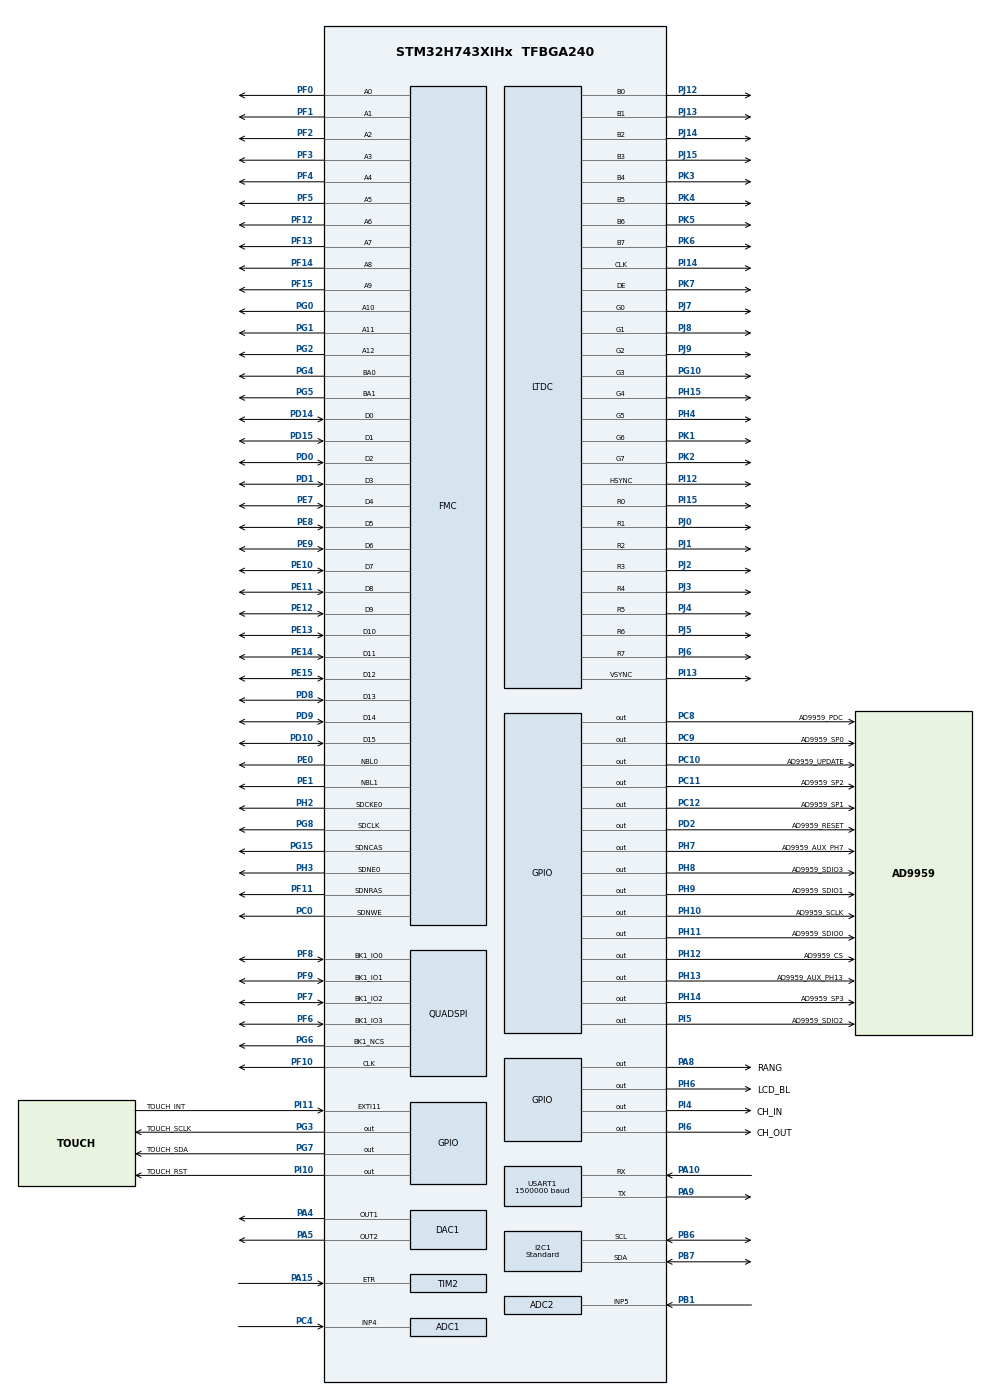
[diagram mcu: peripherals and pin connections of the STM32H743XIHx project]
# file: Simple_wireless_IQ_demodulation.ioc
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ADC1.Channel-0\#ChannelRegularConversion=ADC_CHANNEL_4
ADC1.ClockPrescaler=ADC_CLOCK_ASYNC_DIV2
ADC1.ConversionDataManagement=ADC_CONVERSIONDATA_DMA_CIRCULAR
ADC1.ExternalTrigConv=ADC_EXTERNALTRIG_T2_TRGO
ADC1.NbrOfConversionFlag=1
ADC1.OffsetNumber-0\#ChannelRegularConversion=ADC_OFFSET_NONE
ADC1.OffsetSignedSaturation-0\#ChannelRegularConversion=DISABLE
ADC1.Rank-0\#ChannelRegularConversion=1
ADC1.Resolution=ADC_RESOLUTION_14B
ADC1.SamplingTime-0\#ChannelRegularConversion=ADC_SAMPLETIME_1CYCLE_5
ADC1.master=1
ADC2.Channel-0\#ChannelRegularConversion=ADC_CHANNEL_5
ADC2.ClockPrescaler=ADC_CLOCK_ASYNC_DIV2
ADC2.ConversionDataManagement=ADC_CONVERSIONDATA_DMA_CIRCULAR
ADC2.ExternalTrigConv=ADC_EXTERNALTRIG_T2_TRGO
ADC2.NbrOfConversionFlag=1
ADC2.OffsetNumber-0\#ChannelRegularConversion=ADC_OFFSET_NONE
ADC2.OffsetSignedSaturation-0\#ChannelRegularConversion=DISABLE
ADC2.Rank-0\#ChannelRegularConversion=1
ADC2.Resolution=ADC_RESOLUTION_14B
ADC2.SamplingTime-0\#ChannelRegularConversion=ADC_SAMPLETIME_1CYCLE_5
CORTEX_M7.AccessPermission_Spec=MPU_REGION_FULL_ACCESS
CORTEX_M7.BaseAddress_Spec=0xC0000000
CORTEX_M7.CPU_DCache=Enabled
CORTEX_M7.CPU_ICache=Enabled
CORTEX_M7.DisableExec_Spec=MPU_INSTRUCTION_ACCESS_ENABLE
CORTEX_M7.IsCacheable_Spec=MPU_ACCESS_CACHEABLE
CORTEX_M7.IsShareable_Spec=MPU_ACCESS_NOT_SHAREABLE
CORTEX_M7.MPU_Control=MPU_HFNMI_PRIVDEF
CORTEX_M7.Size_Spec=MPU_REGION_SIZE_32MB
CORTEX_M7.SubRegionDisable_Spec=0x0
CORTEX_M7.default_mode_Activation=1
DAC1.DAC_Channel-DAC_OUT1=DAC_CHANNEL_1
DAC1.DAC_Channel-DAC_OUT2=DAC_CHANNEL_2
DAC1.DAC_Trigger-DAC_OUT1=DAC_TRIGGER_T2_TRGO
DAC1.DAC_Trigger-DAC_OUT2=DAC_TRIGGER_T2_TRGO
Dma.ADC1.0.Direction=DMA_PERIPH_TO_MEMORY
Dma.ADC1.0.EventEnable=DISABLE
Dma.ADC1.0.FIFOMode=DMA_FIFOMODE_DISABLE
Dma.ADC1.0.Instance=DMA1_Stream0
Dma.ADC1.0.MemDataAlignment=DMA_MDATAALIGN_HALFWORD
Dma.ADC1.0.MemInc=DMA_MINC_ENABLE
Dma.ADC1.0.Mode=DMA_CIRCULAR
Dma.ADC1.0.PeriphDataAlignment=DMA_PDATAALIGN_HALFWORD
Dma.ADC1.0.PeriphInc=DMA_PINC_DISABLE
Dma.ADC1.0.Polarity=HAL_DMAMUX_REQ_GEN_RISING
Dma.ADC1.0.Priority=DMA_PRIORITY_VERY_HIGH
Dma.ADC1.0.RequestNumber=1
Dma.ADC1.0.SignalID=NONE
Dma.ADC1.0.SyncEnable=DISABLE
Dma.ADC1.0.SyncPolarity=HAL_DMAMUX_SYNC_NO_EVENT
Dma.ADC1.0.SyncRequestNumber=1
Dma.ADC1.0.SyncSignalID=NONE
Dma.ADC2.1.Direction=DMA_PERIPH_TO_MEMORY
Dma.ADC2.1.EventEnable=DISABLE
Dma.ADC2.1.FIFOMode=DMA_FIFOMODE_DISABLE
Dma.ADC2.1.Instance=DMA2_Stream0
Dma.ADC2.1.MemDataAlignment=DMA_MDATAALIGN_HALFWORD
Dma.ADC2.1.MemInc=DMA_MINC_ENABLE
Dma.ADC2.1.Mode=DMA_CIRCULAR
Dma.ADC2.1.PeriphDataAlignment=DMA_PDATAALIGN_HALFWORD
Dma.ADC2.1.PeriphInc=DMA_PINC_DISABLE
Dma.ADC2.1.Polarity=HAL_DMAMUX_REQ_GEN_RISING
Dma.ADC2.1.Priority=DMA_PRIORITY_VERY_HIGH
Dma.ADC2.1.RequestNumber=1
Dma.ADC2.1.SignalID=NONE
Dma.ADC2.1.SyncEnable=DISABLE
Dma.ADC2.1.SyncPolarity=HAL_DMAMUX_SYNC_NO_EVENT
Dma.ADC2.1.SyncRequestNumber=1
Dma.ADC2.1.SyncSignalID=NONE
Dma.DAC1_CH2.2.Direction=DMA_MEMORY_TO_PERIPH
Dma.DAC1_CH2.2.EventEnable=DISABLE
Dma.DAC1_CH2.2.FIFOMode=DMA_FIFOMODE_DISABLE
Dma.DAC1_CH2.2.Instance=DMA1_Stream1
Dma.DAC1_CH2.2.MemDataAlignment=DMA_MDATAALIGN_HALFWORD
Dma.DAC1_CH2.2.MemInc=DMA_MINC_ENABLE
Dma.DAC1_CH2.2.Mode=DMA_CIRCULAR
Dma.DAC1_CH2.2.PeriphDataAlignment=DMA_PDATAALIGN_HALFWORD
Dma.DAC1_CH2.2.PeriphInc=DMA_PINC_DISABLE
Dma.DAC1_CH2.2.Polarity=HAL_DMAMUX_REQ_GEN_RISING
Dma.DAC1_CH2.2.Priority=DMA_PRIORITY_HIGH
Dma.DAC1_CH2.2.RequestNumber=1
Dma.DAC1_CH2.2.SignalID=NONE
Dma.DAC1_CH2.2.SyncEnable=DISABLE
Dma.DAC1_CH2.2.SyncPolarity=HAL_DMAMUX_SYNC_NO_EVENT
Dma.DAC1_CH2.2.SyncRequestNumber=1
Dma.DAC1_CH2.2.SyncSignalID=NONE
Dma.Request0=ADC1
Dma.Request1=ADC2
Dma.Request2=DAC1_CH2
FMC.CASLatency1=FMC_SDRAM_CAS_LATENCY_3
FMC.ColumnBitsNumber1=FMC_SDRAM_COLUMN_BITS_NUM_9
FMC.ExitSelfRefreshDelay1=7
FMC.LoadToActiveDelay1=2
FMC.RCDDelay1=2
FMC.RPDelay1=2
FMC.ReadBurst1=FMC_SDRAM_RBURST_ENABLE
FMC.ReadPipeDelay1=FMC_SDRAM_RPIPE_DELAY_1
FMC.RowCycleDelay1=7
FMC.SDClockPeriod1=FMC_SDRAM_CLOCK_PERIOD_2
FMC.SelfRefreshTime1=4
FMC.WriteRecoveryTime1=3
FREERTOS.BinarySemaphores01=AdcFrameReadySem,Dynamic,NULL,Depleted;SweepBlockReadySem,Dynamic,NULL,Available;DemodBlockReadySem,Dynamic,NULL,Available
FREERTOS.Queues01=DDSQueue,200,AppDdsCmd,0,Dynamic,NULL,NULL;PrintQueue,32,128,1,Dynamic,NULL,NULL;ModDetectQueue,8,uint32_t,0,Dynamic,NULL,NULL;DemodQueue,4,uint32_t,0,Dynamic,NULL,NULL
FREERTOS.Tasks01=DisplayTask,24,4096,StartDisplayTask,As weak,NULL,Dynamic,NULL,NULL;TouchTask,8,512,StartTouchTask,As weak,NULL,Dynamic,NULL,NULL;DDSTask,40,256,StartDDSTask,As weak,NULL,Dynamic,NULL,NULL;PrintfTask,8,512,StartPrintfTask,As weak,NULL,Dynamic,NULL,NULL;AdcTask,32,1024,StartAdcTask,As weak,NULL,Dynamic,NULL,NULL;ModDetectTask,24,1024,StartModDetectTask,As weak,NULL,Dynamic,NULL,NULL;DemodTask,24,1024,StartDemodTask,As weak,NULL,Dynamic,NULL,NULL;SI5351,8,1024,StartSI5351,As weak,NULL,Dynamic,NULL,NULL
FREERTOS.configTOTAL_HEAP_SIZE=65536
I2C1.I2C_Speed_Mode=I2C_Standard
I2C1.Timing=0x307075B1
LTDC.ActiveW=800
LTDC.Alpha_L0=255
LTDC.FBStartAdress_L0=0xC0000000
LTDC.HBP=80
LTDC.HFP=200
LTDC.HSync=1
LTDC.ImageHeight_L0=480
LTDC.ImageWidth_L0=800
LTDC.Layers=0
LTDC.PixelFormat_L0=LTDC_PIXEL_FORMAT_RGB565
LTDC.VBP=40
LTDC.VFP=22
LTDC.VSync=1
LTDC.WindowX1_L0=800
LTDC.WindowY1_L0=480
Mcu.Family=STM32H7
Mcu.Name=STM32H743XIHx
Mcu.Package=TFBGA240
NVIC.DMA1_Stream0_IRQn=true\:5\:0\:false\:false\:true\:true\:false\:true\:true
NVIC.DMA1_Stream1_IRQn=true\:5\:0\:false\:false\:true\:true\:false\:true\:true
NVIC.DMA2_Stream0_IRQn=true\:5\:0\:false\:false\:true\:false\:false\:true\:true
NVIC.EXTI15_10_IRQn=true\:6\:0\:true\:false\:true\:false\:true\:true\:true
NVIC.PriorityGroup=NVIC_PRIORITYGROUP_4
NVIC.TIM7_IRQn=true\:15\:0\:false\:false\:true\:false\:false\:true\:true
NVIC.TimeBase=TIM7_IRQn
NVIC.TimeBaseIP=TIM7
NVIC.USART1_IRQn=true\:5\:0\:false\:false\:true\:true\:true\:true\:true
PA10.Mode=Asynchronous
PA10.Signal=USART1_RX
PA13\ (JTMS/SWDIO).Mode=Serial_Wire
PA13\ (JTMS/SWDIO).Signal=DEBUG_JTMS-SWDIO
PA14\ (JTCK/SWCLK).Mode=Serial_Wire
PA14\ (JTCK/SWCLK).Signal=DEBUG_JTCK-SWCLK
PA15\ (JTDI).Signal=S_TIM2_CH1_ETR
PA4.Signal=COMP_DAC11_group
PA5.Signal=COMP_DAC12_group
PA8.GPIO_Label=RANG
PA8.Signal=GPIO_Output
PA9.Mode=Asynchronous
PA9.Signal=USART1_TX
PB1.Signal=SharedAnalog_PB1
PB6.GPIO_Pu=GPIO_PULLUP
PB6.Mode=I2C
PB6.Signal=I2C1_SCL
PB7.GPIO_Pu=GPIO_PULLUP
PB7.Mode=I2C
PB7.Signal=I2C1_SDA
PC0.Signal=FMC_SDNWE
PC10.GPIO_Label=AD9959_UPDATE
PC10.GPIO_Speed=GPIO_SPEED_FREQ_VERY_HIGH
PC10.Signal=GPIO_Output
PC11.GPIO_Label=AD9959_SP2
PC11.GPIO_Speed=GPIO_SPEED_FREQ_VERY_HIGH
PC11.Signal=GPIO_Output
PC12.GPIO_Label=AD9959_SP1
PC12.GPIO_Speed=GPIO_SPEED_FREQ_VERY_HIGH
PC12.Signal=GPIO_Output
PC4.Signal=ADCx_INP4
PC8.GPIO_Label=AD9959_PDC
PC8.GPIO_Speed=GPIO_SPEED_FREQ_VERY_HIGH
PC8.Signal=GPIO_Output
PC9.GPIO_Label=AD9959_SP0
PC9.GPIO_Speed=GPIO_SPEED_FREQ_VERY_HIGH
PC9.Signal=GPIO_Output
PD0.Signal=FMC_D2_DA2
PD1.Signal=FMC_D3_DA3
PD10.Signal=FMC_D15_DA15
PD14.Signal=FMC_D0_DA0
PD15.Signal=FMC_D1_DA1
PD2.GPIO_Label=AD9959_RESET
PD2.GPIO_Speed=GPIO_SPEED_FREQ_VERY_HIGH
PD2.Signal=GPIO_Output
PD8.Signal=FMC_D13_DA13
PD9.Signal=FMC_D14_DA14
PE0.Signal=FMC_NBL0
PE1.Signal=FMC_NBL1
PE10.Signal=FMC_D7_DA7
PE11.Signal=FMC_D8_DA8
PE12.Signal=FMC_D9_DA9
PE13.Signal=FMC_D10_DA10
PE14.Signal=FMC_D11_DA11
PE15.Signal=FMC_D12_DA12
PE7.Signal=FMC_D4_DA4
PE8.Signal=FMC_D5_DA5
PE9.Signal=FMC_D6_DA6
PF0.Signal=FMC_A0
PF1.Signal=FMC_A1
PF10.GPIO_Speed=GPIO_SPEED_FREQ_VERY_HIGH
PF10.Mode=Single Bank 1
PF10.Signal=QUADSPI_CLK
PF11.Signal=FMC_SDNRAS
PF12.Signal=FMC_A6
PF13.Signal=FMC_A7
PF14.Signal=FMC_A8
PF15.Signal=FMC_A9
PF2.Signal=FMC_A2
PF3.Signal=FMC_A3
PF4.Signal=FMC_A4
PF5.Signal=FMC_A5
PF6.GPIO_Speed=GPIO_SPEED_FREQ_VERY_HIGH
PF6.Mode=Single Bank 1
PF6.Signal=QUADSPI_BK1_IO3
PF7.GPIO_Speed=GPIO_SPEED_FREQ_VERY_HIGH
PF7.Mode=Single Bank 1
PF7.Signal=QUADSPI_BK1_IO2
PF8.GPIO_Speed=GPIO_SPEED_FREQ_VERY_HIGH
PF8.Mode=Single Bank 1
PF8.Signal=QUADSPI_BK1_IO0
PF9.GPIO_Speed=GPIO_SPEED_FREQ_VERY_HIGH
PF9.Mode=Single Bank 1
PF9.Signal=QUADSPI_BK1_IO1
PG0.Signal=FMC_A10
PG1.Signal=FMC_A11
PG10.GPIO_Speed=GPIO_SPEED_FREQ_VERY_HIGH
PG10.Mode=RGB888
PG10.Signal=LTDC_G3
PG15.Signal=FMC_SDNCAS
PG2.Signal=FMC_A12
PG3.GPIO_Label=TOUCH_SCLK
PG3.GPIO_ModeDefaultOutputPP=GPIO_MODE_OUTPUT_OD
PG3.GPIO_PuPd=GPIO_NOPULL
PG3.PinState=GPIO_PIN_SET
PG3.Signal=GPIO_Output
PG4.Signal=FMC_A14_BA0
PG5.Signal=FMC_A15_BA1
PG6.GPIO_Speed=GPIO_SPEED_FREQ_VERY_HIGH
PG6.Mode=Single Bank 1
PG6.Signal=QUADSPI_BK1_NCS
PG7.GPIO_Label=TOUCH_SDA
PG7.GPIO_ModeDefaultOutputPP=GPIO_MODE_OUTPUT_OD
PG7.GPIO_PuPd=GPIO_NOPULL
PG7.PinState=GPIO_PIN_SET
PG7.Signal=GPIO_Output
PG8.Signal=FMC_SDCLK
PH0-OSC_IN\ (PH0).Mode=HSE-External-Oscillator
PH0-OSC_IN\ (PH0).Signal=RCC_OSC_IN
PH1-OSC_OUT\ (PH1).Mode=HSE-External-Oscillator
PH1-OSC_OUT\ (PH1).Signal=RCC_OSC_OUT
PH10.GPIO_Label=AD9959_SCLK
PH10.GPIO_Speed=GPIO_SPEED_FREQ_VERY_HIGH
PH10.Signal=GPIO_Output
PH11.GPIO_Label=AD9959_SDIO0
PH11.GPIO_Speed=GPIO_SPEED_FREQ_VERY_HIGH
PH11.Signal=GPIO_Output
PH12.GPIO_Label=AD9959_CS
PH12.GPIO_Speed=GPIO_SPEED_FREQ_VERY_HIGH
PH12.Signal=GPIO_Output
PH13.GPIO_Label=AD9959_AUX_PH13
PH13.Signal=GPIO_Output
PH14.GPIO_Label=AD9959_SP3
PH14.GPIO_Speed=GPIO_SPEED_FREQ_VERY_HIGH
PH14.Signal=GPIO_Output
PH15.GPIO_Speed=GPIO_SPEED_FREQ_VERY_HIGH
PH15.Mode=RGB888
PH15.Signal=LTDC_G4
PH2.Mode=SdramChipSelect1_1
PH2.Signal=FMC_SDCKE0
PH3.Mode=SdramChipSelect1_1
PH3.Signal=FMC_SDNE0
PH4.GPIO_Speed=GPIO_SPEED_FREQ_VERY_HIGH
PH4.Mode=RGB888
PH4.Signal=LTDC_G5
PH6.GPIO_Label=LCD_BL
PH6.Signal=GPIO_Output
PH7.GPIO_Label=AD9959_AUX_PH7
PH7.Signal=GPIO_Output
PH8.GPIO_Label=AD9959_SDIO3
PH8.GPIO_Speed=GPIO_SPEED_FREQ_VERY_HIGH
PH8.Signal=GPIO_Output
PH9.GPIO_Label=AD9959_SDIO1
PH9.GPIO_Speed=GPIO_SPEED_FREQ_VERY_HIGH
PH9.Signal=GPIO_Output
PI10.GPIO_Label=TOUCH_RST
PI10.Signal=GPIO_Output
PI11.GPIO_Label=TOUCH_INT
PI11.GPIO_ModeDefaultEXTI=GPIO_MODE_IT_FALLING
PI11.GPIO_PuPd=GPIO_PULLUP
PI11.Signal=GPXTI11
PI12.GPIO_Speed=GPIO_SPEED_FREQ_VERY_HIGH
PI12.Mode=RGB888
PI12.Signal=LTDC_HSYNC
PI13.GPIO_Speed=GPIO_SPEED_FREQ_VERY_HIGH
PI13.Mode=RGB888
PI13.Signal=LTDC_VSYNC
PI14.GPIO_Speed=GPIO_SPEED_FREQ_VERY_HIGH
PI14.Mode=RGB888
PI14.Signal=LTDC_CLK
PI15.GPIO_Speed=GPIO_SPEED_FREQ_VERY_HIGH
PI15.Mode=RGB888
PI15.Signal=LTDC_R0
PI4.GPIO_Label=CH_IN
PI4.Signal=GPIO_Output
PI5.GPIO_Label=AD9959_SDIO2
PI5.GPIO_Speed=GPIO_SPEED_FREQ_VERY_HIGH
PI5.Signal=GPIO_Output
PI6.GPIO_Label=CH_OUT
PI6.Signal=GPIO_Output
PJ0.GPIO_Speed=GPIO_SPEED_FREQ_VERY_HIGH
PJ0.Mode=RGB888
PJ0.Signal=LTDC_R1
PJ1.GPIO_Speed=GPIO_SPEED_FREQ_VERY_HIGH
PJ1.Mode=RGB888
PJ1.Signal=LTDC_R2
PJ12.GPIO_Speed=GPIO_SPEED_FREQ_VERY_HIGH
PJ12.Mode=RGB888
PJ12.Signal=LTDC_B0
PJ13.GPIO_Speed=GPIO_SPEED_FREQ_VERY_HIGH
PJ13.Mode=RGB888
PJ13.Signal=LTDC_B1
PJ14.GPIO_Speed=GPIO_SPEED_FREQ_VERY_HIGH
PJ14.Mode=RGB888
PJ14.Signal=LTDC_B2
PJ15.GPIO_Speed=GPIO_SPEED_FREQ_VERY_HIGH
PJ15.Mode=RGB888
PJ15.Signal=LTDC_B3
PJ2.GPIO_Speed=GPIO_SPEED_FREQ_VERY_HIGH
PJ2.Mode=RGB888
PJ2.Signal=LTDC_R3
PJ3.GPIO_Speed=GPIO_SPEED_FREQ_VERY_HIGH
PJ3.Mode=RGB888
PJ3.Signal=LTDC_R4
PJ4.GPIO_Speed=GPIO_SPEED_FREQ_VERY_HIGH
PJ4.Mode=RGB888
PJ4.Signal=LTDC_R5
PJ5.GPIO_Speed=GPIO_SPEED_FREQ_VERY_HIGH
PJ5.Mode=RGB888
PJ5.Signal=LTDC_R6
PJ6.GPIO_Speed=GPIO_SPEED_FREQ_VERY_HIGH
PJ6.Mode=RGB888
PJ6.Signal=LTDC_R7
PJ7.GPIO_Speed=GPIO_SPEED_FREQ_VERY_HIGH
PJ7.Mode=RGB888
PJ7.Signal=LTDC_G0
PJ8.GPIO_Speed=GPIO_SPEED_FREQ_VERY_HIGH
PJ8.Mode=RGB888
PJ8.Signal=LTDC_G1
PJ9.GPIO_Speed=GPIO_SPEED_FREQ_VERY_HIGH
PJ9.Mode=RGB888
PJ9.Signal=LTDC_G2
PK1.GPIO_Speed=GPIO_SPEED_FREQ_VERY_HIGH
PK1.Mode=RGB888
PK1.Signal=LTDC_G6
PK2.GPIO_Speed=GPIO_SPEED_FREQ_VERY_HIGH
PK2.Mode=RGB888
PK2.Signal=LTDC_G7
PK3.GPIO_Speed=GPIO_SPEED_FREQ_VERY_HIGH
PK3.Mode=RGB888
PK3.Signal=LTDC_B4
PK4.GPIO_Speed=GPIO_SPEED_FREQ_VERY_HIGH
PK4.Mode=RGB888
PK4.Signal=LTDC_B5
PK5.GPIO_Speed=GPIO_SPEED_FREQ_VERY_HIGH
PK5.Mode=RGB888
PK5.Signal=LTDC_B6
PK6.GPIO_Speed=GPIO_SPEED_FREQ_VERY_HIGH
PK6.Mode=RGB888
PK6.Signal=LTDC_B7
PK7.GPIO_Speed=GPIO_SPEED_FREQ_VERY_HIGH
PK7.Mode=RGB888
PK7.Signal=LTDC_DE
ProjectManager.HeapSize=0x200
ProjectManager.StackSize=0x400
ProjectManager.TargetToolchain=CMake
QUADSPI.ClockMode=QSPI_CLOCK_MODE_3
QUADSPI.ClockPrescaler=15
QUADSPI.FifoThreshold=32
QUADSPI.FlashSize=22
QUADSPI.SampleShifting=QSPI_SAMPLE_SHIFTING_HALFCYCLE
RCC.ADCFreq_Value=75000000
RCC.APB1Freq_Value=120000000
RCC.APB2Freq_Value=120000000
RCC.APB3Freq_Value=120000000
RCC.APB4Freq_Value=120000000
RCC.CortexFreq_Value=480000000
RCC.D1PPRE=RCC_APB3_DIV2
RCC.D2PPRE1=RCC_APB1_DIV2
RCC.D2PPRE2=RCC_APB2_DIV2
RCC.D3PPRE=RCC_APB4_DIV2
RCC.DIVM1=5
RCC.DIVM2=2
RCC.DIVM3=1
RCC.DIVN1=192
RCC.DIVN2=12
RCC.DIVN3=6
RCC.DIVQ1=4
RCC.DIVR3=4
RCC.HCLKFreq_Value=240000000
RCC.HPRE=RCC_HCLK_DIV2
RCC.PLL2FRACN=0
RCC.PLL3FRACN=0
RCC.PLLFRACN=0
RCC.PLLSourceVirtual=RCC_PLLSOURCE_HSE
RCC.SYSCLKFreq_VALUE=480000000
RCC.SYSCLKSource=RCC_SYSCLKSOURCE_PLLCLK
RCC.USBFreq_Value=240000000
SH.ADCx_INP4.0=ADC1_INP4,IN4-Single-Ended
SH.COMP_DAC11_group.0=DAC1_OUT1,DAC_OUT1
SH.COMP_DAC12_group.0=DAC1_OUT2,DAC_OUT2
SH.FMC_A0.0=FMC_A0,13b-sda1
SH.FMC_A1.0=FMC_A1,13b-sda1
SH.FMC_A10.0=FMC_A10,13b-sda1
SH.FMC_A11.0=FMC_A11,13b-sda1
SH.FMC_A12.0=FMC_A12,13b-sda1
SH.FMC_A14_BA0.0=FMC_BA0,FourSdramBanks1
SH.FMC_A15_BA1.0=FMC_BA1,FourSdramBanks1
SH.FMC_A2.0=FMC_A2,13b-sda1
SH.FMC_A3.0=FMC_A3,13b-sda1
SH.FMC_A4.0=FMC_A4,13b-sda1
SH.FMC_A5.0=FMC_A5,13b-sda1
SH.FMC_A6.0=FMC_A6,13b-sda1
SH.FMC_A7.0=FMC_A7,13b-sda1
SH.FMC_A8.0=FMC_A8,13b-sda1
SH.FMC_A9.0=FMC_A9,13b-sda1
SH.FMC_D0_DA0.0=FMC_D0,sd-16b-d1
SH.FMC_D10_DA10.0=FMC_D10,sd-16b-d1
SH.FMC_D11_DA11.0=FMC_D11,sd-16b-d1
SH.FMC_D12_DA12.0=FMC_D12,sd-16b-d1
SH.FMC_D13_DA13.0=FMC_D13,sd-16b-d1
SH.FMC_D14_DA14.0=FMC_D14,sd-16b-d1
SH.FMC_D15_DA15.0=FMC_D15,sd-16b-d1
SH.FMC_D1_DA1.0=FMC_D1,sd-16b-d1
SH.FMC_D2_DA2.0=FMC_D2,sd-16b-d1
SH.FMC_D3_DA3.0=FMC_D3,sd-16b-d1
SH.FMC_D4_DA4.0=FMC_D4,sd-16b-d1
SH.FMC_D5_DA5.0=FMC_D5,sd-16b-d1
SH.FMC_D6_DA6.0=FMC_D6,sd-16b-d1
SH.FMC_D7_DA7.0=FMC_D7,sd-16b-d1
SH.FMC_D8_DA8.0=FMC_D8,sd-16b-d1
SH.FMC_D9_DA9.0=FMC_D9,sd-16b-d1
SH.FMC_NBL0.0=FMC_NBL0,Sd2ByteEnable1
SH.FMC_NBL1.0=FMC_NBL1,Sd2ByteEnable1
SH.FMC_SDCLK.0=FMC_SDCLK,13b-sda1
SH.FMC_SDNCAS.0=FMC_SDNCAS,13b-sda1
SH.FMC_SDNRAS.0=FMC_SDNRAS,13b-sda1
SH.FMC_SDNWE.0=FMC_SDNWE,13b-sda1
SH.S_TIM2_CH1_ETR.0=TIM2_ETR,ClockSourceETR_Mode2
SH.SharedAnalog_PB1.0=COMP1_INM
SH.SharedAnalog_PB1.1=ADC2_INP5,IN5-Single-Ended
TIM2.Period=10-1
TIM2.TIM_MasterOutputTrigger=TIM_TRGO_UPDATE
TIM6.Period=75-1
TIM6.TIM_MasterOutputTrigger=TIM_TRGO_UPDATE
USART1.BaudRate=1500000
USART1.VirtualMode-Asynchronous=VM_ASYNC
VP_FREERTOS_VS_CMSIS_V2.Mode=CMSIS_V2
VP_MEMORYMAP_VS_MEMORYMAP.Mode=CurAppReg
VP_SYS_VS_tim7.Mode=TIM7
VP_TIM6_VS_ClockSourceINT.Mode=Enable_Timer
board=custom

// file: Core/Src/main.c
/* USER CODE BEGIN Header */
/**
  ******************************************************************************
  * @file           : main.c
  * @brief          : Main program body
  ******************************************************************************
  * @attention
  *
  * Copyright (c) 2026 STMicroelectronics.
  * All rights reserved.
  *
  * This software is licensed under terms that can be found in the LICENSE file
  * in the root directory of this software component.
  * If no LICENSE file comes with this software, it is provided AS-IS.
  *
  ******************************************************************************
  */
/* USER CODE END Header */
#include "main.h"
#include "FreeRTOS.h"
#include "cmsis_os2.h"
#include "adc.h"
#include "dac.h"
#include "dma.h"
#include "i2c.h"
#include "ltdc.h"
#include "quadspi.h"
#include "tim.h"
#include "usart.h"
#include "gpio.h"
#include "fmc.h"

/* USER CODE BEGIN Includes */
#include <stdint.h>
#include <stdio.h>
#include <string.h>
/* USER CODE END Includes */

void SystemClock_Config(void);
void PeriphCommonClock_Config(void);
static void MPU_Config(void);
void MX_FREERTOS_Init(void);

int main(void)
{

  /* MPU Configuration--------------------------------------------------------*/
  MPU_Config();

  /* Enable the CPU Cache */

  /* Enable I-Cache---------------------------------------------------------*/
  SCB_EnableICache();

  /* Enable D-Cache---------------------------------------------------------*/
  SCB_EnableDCache();

  /* MCU Configuration--------------------------------------------------------*/

  /* Reset of all peripherals, Initializes the Flash interface and the Systick. */
  HAL_Init();

  /* USER CODE BEGIN Init */
  SCB->SHCSR |= (SCB_SHCSR_USGFAULTENA_Msk |
                 SCB_SHCSR_BUSFAULTENA_Msk |
                 SCB_SHCSR_MEMFAULTENA_Msk);
  /* Keep divide-by-zero trap disabled for now. */
//  SCB->CCR |= SCB_CCR_DIV_0_TRP_Msk;  // Enable later if divide-by-zero trapping is required.
  SCB->CCR &= ~SCB_CCR_UNALIGN_TRP_Msk; // LVGL 8.3.x may issue unaligned accesses on this target.
  /* USER CODE END Init */

  /* Configure the system clock */
  SystemClock_Config();

  /* Configure the peripherals common clocks */
  PeriphCommonClock_Config();

  /* Initialize all configured peripherals */
  MX_GPIO_Init();
  MX_DMA_Init();
  MX_FMC_Init();
  MX_LTDC_Init();
  MX_USART1_UART_Init();
  MX_ADC1_Init();
  MX_ADC2_Init();
  MX_TIM6_Init();
  MX_I2C1_Init();
  MX_TIM2_Init();
  MX_DAC1_Init();
  MX_QUADSPI_Init();

  /* Init scheduler */
  osKernelInitialize();  /* Call init function for freertos objects (in cmsis_os2.c) */
  MX_FREERTOS_Init();

  /* Start scheduler */
  osKernelStart();

  /* We should never get here as control is now taken by the scheduler */

  /* Infinite loop */
  while (1)
  {

  }
}

void SystemClock_Config(void)
{
  RCC_OscInitTypeDef RCC_OscInitStruct = {0};
  RCC_ClkInitTypeDef RCC_ClkInitStruct = {0};

  /** Supply configuration update enable
  */
  HAL_PWREx_ConfigSupply(PWR_LDO_SUPPLY);

  /** Configure the main internal regulator output voltage
  */
  __HAL_PWR_VOLTAGESCALING_CONFIG(PWR_REGULATOR_VOLTAGE_SCALE0);

  while(!__HAL_PWR_GET_FLAG(PWR_FLAG_VOSRDY)) {}

  /** Initializes the RCC Oscillators according to the specified parameters
  * in the RCC_OscInitTypeDef structure.
  */
  RCC_OscInitStruct.OscillatorType = RCC_OSCILLATORTYPE_HSE;
  RCC_OscInitStruct.HSEState = RCC_HSE_ON;
  RCC_OscInitStruct.PLL.PLLState = RCC_PLL_ON;
  RCC_OscInitStruct.PLL.PLLSource = RCC_PLLSOURCE_HSE;
  RCC_OscInitStruct.PLL.PLLM = 5;
  RCC_OscInitStruct.PLL.PLLN = 192;
  RCC_OscInitStruct.PLL.PLLP = 2;
  RCC_OscInitStruct.PLL.PLLQ = 4;
  RCC_OscInitStruct.PLL.PLLR = 2;
  RCC_OscInitStruct.PLL.PLLRGE = RCC_PLL1VCIRANGE_2;
  RCC_OscInitStruct.PLL.PLLVCOSEL = RCC_PLL1VCOWIDE;
  RCC_OscInitStruct.PLL.PLLFRACN = 0;
  if (HAL_RCC_OscConfig(&RCC_OscInitStruct) != HAL_OK)
  {
    Error_Handler();
  }

  /** Initializes the CPU, AHB and APB buses clocks
  */
  RCC_ClkInitStruct.ClockType = RCC_CLOCKTYPE_HCLK|RCC_CLOCKTYPE_SYSCLK
                              |RCC_CLOCKTYPE_PCLK1|RCC_CLOCKTYPE_PCLK2
                              |RCC_CLOCKTYPE_D3PCLK1|RCC_CLOCKTYPE_D1PCLK1;
  RCC_ClkInitStruct.SYSCLKSource = RCC_SYSCLKSOURCE_PLLCLK;
  RCC_ClkInitStruct.SYSCLKDivider = RCC_SYSCLK_DIV1;
  RCC_ClkInitStruct.AHBCLKDivider = RCC_HCLK_DIV2;
  RCC_ClkInitStruct.APB3CLKDivider = RCC_APB3_DIV2;
  RCC_ClkInitStruct.APB1CLKDivider = RCC_APB1_DIV2;
  RCC_ClkInitStruct.APB2CLKDivider = RCC_APB2_DIV2;
  RCC_ClkInitStruct.APB4CLKDivider = RCC_APB4_DIV2;

  if (HAL_RCC_ClockConfig(&RCC_ClkInitStruct, FLASH_LATENCY_4) != HAL_OK)
  {
    Error_Handler();
  }
}

void PeriphCommonClock_Config(void)
{
  RCC_PeriphCLKInitTypeDef PeriphClkInitStruct = {0};

  /** Initializes the peripherals clock
  */
  PeriphClkInitStruct.PeriphClockSelection = RCC_PERIPHCLK_ADC;
  PeriphClkInitStruct.PLL2.PLL2M = 2;
  PeriphClkInitStruct.PLL2.PLL2N = 12;
  PeriphClkInitStruct.PLL2.PLL2P = 2;
  PeriphClkInitStruct.PLL2.PLL2Q = 2;
  PeriphClkInitStruct.PLL2.PLL2R = 2;
  PeriphClkInitStruct.PLL2.PLL2RGE = RCC_PLL2VCIRANGE_3;
  PeriphClkInitStruct.PLL2.PLL2VCOSEL = RCC_PLL2VCOMEDIUM;
  PeriphClkInitStruct.PLL2.PLL2FRACN = 0;
  PeriphClkInitStruct.AdcClockSelection = RCC_ADCCLKSOURCE_PLL2;
  if (HAL_RCCEx_PeriphCLKConfig(&PeriphClkInitStruct) != HAL_OK)
  {
    Error_Handler();
  }
}

 /* MPU Configuration */

void MPU_Config(void)
{
  MPU_Region_InitTypeDef MPU_InitStruct = {0};

  /* Disables the MPU */
  HAL_MPU_Disable();

  /** Initializes and configures the Region and the memory to be protected
  */
  MPU_InitStruct.Enable = MPU_REGION_ENABLE;
  MPU_InitStruct.Number = MPU_REGION_NUMBER0;
  MPU_InitStruct.BaseAddress = 0xC0000000;
  MPU_InitStruct.Size = MPU_REGION_SIZE_32MB;
  MPU_InitStruct.SubRegionDisable = 0x0;
  MPU_InitStruct.TypeExtField = MPU_TEX_LEVEL0;
  MPU_InitStruct.AccessPermission = MPU_REGION_FULL_ACCESS;
  MPU_InitStruct.DisableExec = MPU_INSTRUCTION_ACCESS_ENABLE;
  MPU_InitStruct.IsShareable = MPU_ACCESS_NOT_SHAREABLE;
  MPU_InitStruct.IsCacheable = MPU_ACCESS_CACHEABLE;
  MPU_InitStruct.IsBufferable = MPU_ACCESS_NOT_BUFFERABLE;

  HAL_MPU_ConfigRegion(&MPU_InitStruct);
  /* Enables the MPU */
  HAL_MPU_Enable(MPU_HFNMI_PRIVDEF);

}

void HAL_TIM_PeriodElapsedCallback(TIM_HandleTypeDef *htim)
{
  if (htim->Instance == TIM7)
  {
    HAL_IncTick();
  }
}

void Error_Handler(void)
{
  __disable_irq();
  while (1)
  {
  }
}

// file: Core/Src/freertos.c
/* USER CODE BEGIN Header */
/**
  ******************************************************************************
  * File Name          : freertos.c
  * Description        : Code for freertos applications
  ******************************************************************************
  * @attention
  *
  * Copyright (c) 2026 STMicroelectronics.
  * All rights reserved.
  *
  * This software is licensed under terms that can be found in the LICENSE file
  * in the root directory of this software component.
  * If no LICENSE file comes with this software, it is provided AS-IS.
  *
  ******************************************************************************
  */
/* USER CODE END Header */

#include "FreeRTOS.h"
#include "task.h"
#include "main.h"
#include "FreeRTOS.h"
#include "cmsis_os2.h"

/* USER CODE BEGIN Includes */
#include "app_dds_ctrl.h" // DDS command queue type
#include "app_board_flash.h"
/* USER CODE END Includes */

/* Definitions for DisplayTask */
osThreadId_t DisplayTaskHandle;
const osThreadAttr_t DisplayTask_attributes = {
  .name = "DisplayTask",
  .stack_size = 4096 * 4,
  .priority = (osPriority_t) osPriorityNormal,
};
/* Definitions for TouchTask */
osThreadId_t TouchTaskHandle;
const osThreadAttr_t TouchTask_attributes = {
  .name = "TouchTask",
  .stack_size = 512 * 4,
  .priority = (osPriority_t) osPriorityLow,
};
/* Definitions for DDSTask */
osThreadId_t DDSTaskHandle;
const osThreadAttr_t DDSTask_attributes = {
  .name = "DDSTask",
  .stack_size = 256 * 4,
  .priority = (osPriority_t) osPriorityHigh,
};
/* Definitions for PrintfTask */
osThreadId_t PrintfTaskHandle;
const osThreadAttr_t PrintfTask_attributes = {
  .name = "PrintfTask",
  .stack_size = 512 * 4,
  .priority = (osPriority_t) osPriorityLow,
};
/* Definitions for AdcTask */
osThreadId_t AdcTaskHandle;
const osThreadAttr_t AdcTask_attributes = {
  .name = "AdcTask",
  .stack_size = 1024 * 4,
  .priority = (osPriority_t) osPriorityAboveNormal,
};
/* Definitions for ModDetectTask */
osThreadId_t ModDetectTaskHandle;
const osThreadAttr_t ModDetectTask_attributes = {
  .name = "ModDetectTask",
  .stack_size = 1024 * 4,
  .priority = (osPriority_t) osPriorityNormal,
};
/* Definitions for DemodTask */
osThreadId_t DemodTaskHandle;
const osThreadAttr_t DemodTask_attributes = {
  .name = "DemodTask",
  .stack_size = 1024 * 4,
  .priority = (osPriority_t) osPriorityNormal,
};
/* Definitions for SI5351 */
osThreadId_t SI5351Handle;
const osThreadAttr_t SI5351_attributes = {
  .name = "SI5351",
  .stack_size = 1024 * 4,
  .priority = (osPriority_t) osPriorityLow,
};
/* Definitions for DDSQueue */
osMessageQueueId_t DDSQueueHandle;
const osMessageQueueAttr_t DDSQueue_attributes = {
  .name = "DDSQueue"
};
/* Definitions for PrintQueue */
osMessageQueueId_t PrintQueueHandle;
const osMessageQueueAttr_t PrintQueue_attributes = {
  .name = "PrintQueue"
};
/* Definitions for ModDetectQueue */
osMessageQueueId_t ModDetectQueueHandle;
const osMessageQueueAttr_t ModDetectQueue_attributes = {
  .name = "ModDetectQueue"
};
/* Definitions for DemodQueue */
osMessageQueueId_t DemodQueueHandle;
const osMessageQueueAttr_t DemodQueue_attributes = {
  .name = "DemodQueue"
};
/* Definitions for AdcFrameReadySem */
osSemaphoreId_t AdcFrameReadySemHandle;
const osSemaphoreAttr_t AdcFrameReadySem_attributes = {
  .name = "AdcFrameReadySem"
};
/* Definitions for SweepBlockReadySem */
osSemaphoreId_t SweepBlockReadySemHandle;
const osSemaphoreAttr_t SweepBlockReadySem_attributes = {
  .name = "SweepBlockReadySem"
};
/* Definitions for DemodBlockReadySem */
osSemaphoreId_t DemodBlockReadySemHandle;
const osSemaphoreAttr_t DemodBlockReadySem_attributes = {
  .name = "DemodBlockReadySem"
};

void StartDisplayTask(void *argument);
void StartTouchTask(void *argument);
void StartDDSTask(void *argument);
void StartPrintfTask(void *argument);
void StartAdcTask(void *argument);
void StartModDetectTask(void *argument);
void StartDemodTask(void *argument);
void StartSI5351(void *argument);

void MX_FREERTOS_Init(void); /* (MISRA C 2004 rule 8.1) */

void MX_FREERTOS_Init(void) {

  /* USER CODE BEGIN RTOS_MUTEX */
  /* Serialize QSPI users: settings saves, sweep calibration and optional wallpaper asset. */
  app_board_flash_rtos_init();
  /* USER CODE END RTOS_MUTEX */

  /* Create the semaphores(s) */
  /* creation of AdcFrameReadySem */
  AdcFrameReadySemHandle = osSemaphoreNew(1, 0, &AdcFrameReadySem_attributes);

  /* creation of SweepBlockReadySem */
  SweepBlockReadySemHandle = osSemaphoreNew(1, 1, &SweepBlockReadySem_attributes);

  /* creation of DemodBlockReadySem */
  DemodBlockReadySemHandle = osSemaphoreNew(1, 1, &DemodBlockReadySem_attributes);

  /* Create the queue(s) */
  /* creation of DDSQueue */
  DDSQueueHandle = osMessageQueueNew (200, sizeof(AppDdsCmd), &DDSQueue_attributes);

  /* creation of PrintQueue */
  PrintQueueHandle = osMessageQueueNew (32, 128, &PrintQueue_attributes);

  /* creation of ModDetectQueue */
  ModDetectQueueHandle = osMessageQueueNew (8, sizeof(uint32_t), &ModDetectQueue_attributes);

  /* creation of DemodQueue */
  DemodQueueHandle = osMessageQueueNew (4, sizeof(uint32_t), &DemodQueue_attributes);

  /* USER CODE BEGIN RTOS_QUEUES */
  (void)AppDDS_BindRtosQueue(DDSQueueHandle);
  /* USER CODE END RTOS_QUEUES */

  /* Create the thread(s) */
  /* creation of DisplayTask */
  DisplayTaskHandle = osThreadNew(StartDisplayTask, NULL, &DisplayTask_attributes);

  /* creation of TouchTask */
  TouchTaskHandle = osThreadNew(StartTouchTask, NULL, &TouchTask_attributes);

  /* creation of DDSTask */
  DDSTaskHandle = osThreadNew(StartDDSTask, NULL, &DDSTask_attributes);

  /* creation of PrintfTask */
  PrintfTaskHandle = osThreadNew(StartPrintfTask, NULL, &PrintfTask_attributes);

  /* creation of AdcTask */
  AdcTaskHandle = osThreadNew(StartAdcTask, NULL, &AdcTask_attributes);

  /* creation of ModDetectTask */
  ModDetectTaskHandle = osThreadNew(StartModDetectTask, NULL, &ModDetectTask_attributes);

  /* creation of DemodTask */
  DemodTaskHandle = osThreadNew(StartDemodTask, NULL, &DemodTask_attributes);

  /* creation of SI5351 */
  SI5351Handle = osThreadNew(StartSI5351, NULL, &SI5351_attributes);

  /* USER CODE BEGIN RTOS_THREADS */
  /* Keep touch responsive while demod is active. */
  if (TouchTaskHandle != NULL)
  {
    (void)osThreadSetPriority(TouchTaskHandle, osPriorityNormal);
  }
  if (DemodTaskHandle != NULL)
  {
    (void)osThreadSetPriority(DemodTaskHandle, osPriorityBelowNormal);
  }
  /* add threads, ... */
  /* USER CODE END RTOS_THREADS */

}

__weak void StartDisplayTask(void *argument)
{
  for(;;)
  {
    osDelay(1);
  }
}

__weak void StartTouchTask(void *argument)
{
  for(;;)
  {
    osDelay(1);
  }
}

__weak void StartDDSTask(void *argument)
{
  for(;;)
  {
    osDelay(1);
  }
}

__weak void StartPrintfTask(void *argument)
{
  for(;;)
  {
    osDelay(1);
  }
}

__weak void StartAdcTask(void *argument)
{
  for(;;)
  {
    osDelay(1);
  }
}

__weak void StartModDetectTask(void *argument)
{
  for(;;)
  {
    osDelay(1);
  }
}

__weak void StartDemodTask(void *argument)
{
  for(;;)
  {
    osDelay(1);
  }
}

__weak void StartSI5351(void *argument)
{
  for(;;)
  {
    osDelay(1);
  }
}
